AUTOSAR XML (schema 4-0-3)
package /ComponentTypes
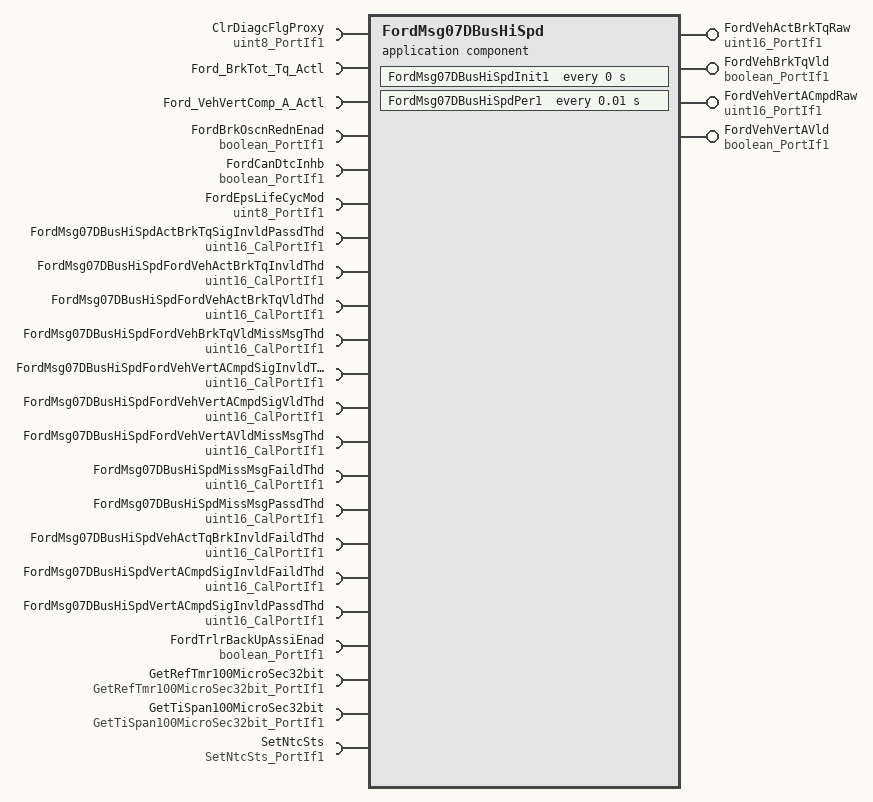
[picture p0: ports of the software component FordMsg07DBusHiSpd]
  application sw component type FordMsg07DBusHiSpd  # The purpose of the Ford Message 07D Bus High Speed function is to provide the Electric Power Steering system with signal values for the Brake Oscillation Reduction and Trailer Back Up Assist function from CAN. The Ford Message 07D function will perform the missing message diagnostic, signal invalid diagnostic, and provide a validity flag for the received message and signal values.']
    4 x provide port:
      FordVehActBrkTqRaw: nonqueued-sender-com-spec{data-element=Val, init-value=0}, provided-interface=uint16_PortIf1  # Processed value of Ford Vehicle Actual Brake Torque Raw to be used by EPS
      FordVehBrkTqVld: nonqueued-sender-com-spec{data-element=Logl, init-value=0}, provided-interface=boolean_PortIf1  # This signal Check the validity of Ford Vehicle Brake Torque
      FordVehVertACmpdRaw: nonqueued-sender-com-spec{data-element=Val, init-value=0}, provided-interface=uint16_PortIf1  # Processed value of Ford Vehicle Vertical Acceleration Compensated Raw to be used by EPS
      FordVehVertAVld: nonqueued-sender-com-spec{data-element=Logl, init-value=0}, provided-interface=boolean_PortIf1  # This signal Check the validity of Ford Vehicle Vertical Acceleration
    22 x require port:
      ClrDiagcFlgProxy: nonqueued-receiver-com-spec{data-element=Val, filter=data-filter-type=ALWAYS, init-value=0}, required-interface=uint8_PortIf1  # When ClrDiagcFlgProxy is True, Diagnostic test is performed
      Ford_BrkTot_Tq_Actl: nonqueued-receiver-com-spec{data-element=Ford_BrkTot_Tq_Actl, filter=data-filter-type=ALWAYS, init-value=0}, required-interface=Ford_BrkTot_Tq_Actl  # Ford Brake Total Torque Actual signal is a message signal which is received from CAN bus and which will be processed and used in EPS. Customer Data type : Ford_BrkTot_Tq_Actl,Source signal range: [0,8189], Cx1FFE_Unknown(8190) and Cx1FFF_Fault(8191)
      Ford_VehVertComp_A_Actl: nonqueued-receiver-com-spec{data-element=Ford_VehVertComp_A_Actl, filter=data-filter-type=ALWAYS, init-value=0}, required-interface=Ford_VehVertComp_A_Actl  # Ford Vehicle Vertical Compensated Acceleration Actual signal is a message signal which is received from CAN bus and which will be processed and used in EPS. Customer Data type : Ford_VehVertComp_A_Actl,Source signal range: [0,1021], Cx3FE_NoDataExists(1022) and Cx3FF_Fault(1023)
      FordBrkOscnRednEnad: nonqueued-receiver-com-spec{data-element=Logl, filter=data-filter-type=ALWAYS, init-value=0}, required-interface=boolean_PortIf1  # Ford Brake Oscillation Reduction Enabled signal is a message signal which is received from CAN bus and which will be used for Diagnostics of received message
      FordCanDtcInhb: nonqueued-receiver-com-spec{data-element=Logl, filter=data-filter-type=ALWAYS, init-value=1}, required-interface=boolean_PortIf1  # When CAN DTC Inhibit is FALSE, Diagnostic test is performed
      FordEpsLifeCycMod: nonqueued-receiver-com-spec{data-element=Val, filter=data-filter-type=ALWAYS, init-value=0}, required-interface=uint8_PortIf1  # This signal is used to decide calibration value to FAIL the NTC
      FordMsg07DBusHiSpdActBrkTqSigInvldPassdThd: parameter-require-com-spec{init-value=0, parameter=Val}, required-interface=uint16_CalPortIf1  # Threshold to update the Ford Vehicle Brake Torque Validity signal whenthe Ford Brake Total Torque Actual signal is invalid
      FordMsg07DBusHiSpdFordVehActBrkTqInvldThd: parameter-require-com-spec{init-value=0, parameter=Val}, required-interface=uint16_CalPortIf1  # Threshold to set Ford Vehicle Actual Brake Torque Invalid to False
      FordMsg07DBusHiSpdFordVehActBrkTqVldThd: parameter-require-com-spec{init-value=0, parameter=Val}, required-interface=uint16_CalPortIf1  # Threshold to set Ford Vehicle Actual Brake Torque Valid to True
      FordMsg07DBusHiSpdFordVehBrkTqVldMissMsgThd: parameter-require-com-spec{init-value=5000, parameter=Val}, required-interface=uint16_CalPortIf1  # Threshold to set Ford Vehicle Actual Brake Torque Valid to False
      FordMsg07DBusHiSpdFordVehVertACmpdSigInvldThd: parameter-require-com-spec{init-value=0, parameter=Val}, required-interface=uint16_CalPortIf1  # Threshold to set Ford Vehicle Vertical Acceleration Compensated Signal Invalid to False
      FordMsg07DBusHiSpdFordVehVertACmpdSigVldThd: parameter-require-com-spec{init-value=5000, parameter=Val}, required-interface=uint16_CalPortIf1  # Threshold to set Ford Vehicle Vertical Acceleration Compensated Signal Valid to True
      FordMsg07DBusHiSpdFordVehVertAVldMissMsgThd: parameter-require-com-spec{init-value=5000, parameter=Val}, required-interface=uint16_CalPortIf1  # Threshold to set Ford Vehicle Vertical Acceleration Compensated Signal Invalid to False
      FordMsg07DBusHiSpdMissMsgFaildThd: parameter-require-com-spec{init-value=5000, parameter=Val}, required-interface=uint16_CalPortIf1  # Threshold to set the Missing message NTC
      FordMsg07DBusHiSpdMissMsgPassdThd: parameter-require-com-spec{init-value=0, parameter=Val}, required-interface=uint16_CalPortIf1  # Threshold to reset the Missing message NTC
      FordMsg07DBusHiSpdVehActTqBrkInvldFaildThd: parameter-require-com-spec{init-value=0, parameter=Val}, required-interface=uint16_CalPortIf1  # Threshold to set the Ford Vehicle Actual Torque Brake Invalid NTC
      FordMsg07DBusHiSpdVertACmpdSigInvldFaildThd: parameter-require-com-spec{init-value=0, parameter=Val}, required-interface=uint16_CalPortIf1  # Threshold to set the Ford Vehicle Vertical Acceleration Compensated Signal Invalid NTC
      FordMsg07DBusHiSpdVertACmpdSigInvldPassdThd: parameter-require-com-spec{init-value=0, parameter=Val}, required-interface=uint16_CalPortIf1  # Threshold to reset the Ford Vehicle Vertical Acceleration Compensated Signal Invalid NTC
      FordTrlrBackUpAssiEnad: nonqueued-receiver-com-spec{data-element=Logl, filter=data-filter-type=ALWAYS, init-value=0}, required-interface=boolean_PortIf1  # Ford Trailer Back Up Assist Enabled signal is a message signal which is received from CAN bus and which will be used for Diagnostics of received message
      GetRefTmr100MicroSec32bit: client-com-spec=Oper, required-interface=GetRefTmr100MicroSec32bit_PortIf1  # It captures simulation time fromthe SimnTi value obtained at root layer of model and gives the RefTmr
      GetTiSpan100MicroSec32bit: client-com-spec=Oper, required-interface=GetTiSpan100MicroSec32bit_PortIf1  # It Captures simulation time fromSimnTi value, handles counter wrapping, and subtracts RefTmr,provides the TiSpan
      SetNtcSts: client-com-spec=Oper, required-interface=SetNtcSts_PortIf1  # Returns the NTC Qualifier status
    behavior FordMsg07DBusHiSpd_InternalBehavior
      ar-typed-per-instance-memorys:
        19 x data, all with sw-calibration-access=READ-ONLY:
          ClrDiagcFlgProxyPrev: type=uint8  # Clear Diagc Flag Proxy
          FirstTranVldFlg: type=boolean  # This flag is used to indicate the reception of first message
          FordVehActBrkTqRawPrev: type=uint16  # Holds previous value of FordVehActBrkTqRaw when FordMsg07D message is missing
          FordVehActBrkTqSigInvldFaildRefTi: type=uint32  # Timer for invalid message will increment or reset based on the conditions for NTC0x110
          FordVehActBrkTqSigInvldPassdRefTi: type=uint32  # Timer for invalid message will increment or reset based on the conditions for NTC0x110
          FordVehActBrkTqVldFaildRefTi: type=uint32  # Timer for Ford Vehicle Actual Brake Torque Valid Failed Reference Time will increment or reset based on the conditions
          FordVehActBrkTqVldPassdRefTi: type=uint32  # Timer for Ford Vehicle Actual Brake Torque Valid Passed Reference Time will increment or reset based on the conditions
          FordVehBrkTqVldMissMsgRefTi: type=uint32  # Timer to update Ford Vehicle Brake Torque Valid signal as true or false when FordMsg07D message is missing
          FordVehBrkTqVldPrev: type=boolean  # Holds previous value of FordVehBrkTqVld when FordMsg07D message is missing
          FordVehMsg07DMiss: type=boolean  # Flag for missing message diagnostics, it is true when message is missing
          FordVehVertACmpdRawPrev: type=uint16  # Holds previous value of FordVehVertACmpdRaw when FordMsg07D message is missing
          FordVehVertACmpdSigInvldFaildRefTi: type=uint32  # Timer for invalid message will increment or reset based on the conditions for NTC0x111
          FordVehVertACmpdSigInvldPassdRefTi: type=uint32  # Timer for invalid message will increment or reset based on the conditions for NTC0x111
          FordVehVertACmpdSigVldFaildRefTi: type=uint32  # Timer for Ford Vehicle Vertical Acceleration Compensated Signal Valid Failed Reference Time will increment or reset based on the conditions
          FordVehVertACmpdSigVldPassdRefTi: type=uint32  # Timer for Ford Vehicle Vertical Acceleration Compensated Signal Valid Passed Reference Time will increment or reset based on the conditions
          FordVehVertAVldMissMsgRefTi: type=uint32  # Timer for Ford Vehicle Vertical Acceleration Compensated Signal Valid Missing Reference Time will increment or reset based on the conditions
          FordVehVertAVldPrev: type=boolean  # Previous Value of Ford Vehicle Vertical Acceleration Valid
          MissMsgFaildRefTi: type=uint32  # Timer for missing message will increment or reset based on the conditions
          MissMsgPassdRefTi: type=uint32  # Timer for missing message will increment or reset based on the conditions
      timing event FordMsg07DBusHiSpd_InitEvent: start-on-event=FordMsg07DBusHiSpdInit1, period=0
      timing event TMT_FordMsg07DBusHiSpdPer1: start-on-event=FordMsg07DBusHiSpdPer1, period=0.01
      port-api-options:
        enable-take-address=false, indirect-api=false, port=ClrDiagcFlgProxy
        enable-take-address=false, indirect-api=false, port=Ford_BrkTot_Tq_Actl
        enable-take-address=false, indirect-api=false, port=Ford_VehVertComp_A_Actl
        enable-take-address=false, indirect-api=false, port=FordBrkOscnRednEnad
        enable-take-address=false, indirect-api=false, port=FordCanDtcInhb
        enable-take-address=false, indirect-api=false, port=FordEpsLifeCycMod
        enable-take-address=false, indirect-api=false, port=FordMsg07DBusHiSpdActBrkTqSigInvldPassdThd
        enable-take-address=false, indirect-api=false, port=FordMsg07DBusHiSpdFordVehActBrkTqInvldThd
        enable-take-address=false, indirect-api=false, port=FordMsg07DBusHiSpdFordVehBrkTqVldMissMsgThd
        enable-take-address=false, indirect-api=false, port=FordMsg07DBusHiSpdFordVehVertACmpdSigInvldThd
        enable-take-address=false, indirect-api=false, port=FordMsg07DBusHiSpdFordVehVertACmpdSigVldThd
        enable-take-address=false, indirect-api=false, port=FordMsg07DBusHiSpdFordVehVertAVldMissMsgThd
        enable-take-address=false, indirect-api=false, port=FordMsg07DBusHiSpdMissMsgFaildThd
        enable-take-address=false, indirect-api=false, port=FordMsg07DBusHiSpdMissMsgPassdThd
        enable-take-address=false, indirect-api=false, port=FordMsg07DBusHiSpdVehActTqBrkInvldFaildThd
        enable-take-address=false, indirect-api=false, port=FordMsg07DBusHiSpdVertACmpdSigInvldFaildThd
        enable-take-address=false, indirect-api=false, port=FordMsg07DBusHiSpdVertACmpdSigInvldPassdThd
        enable-take-address=false, indirect-api=false, port=FordTrlrBackUpAssiEnad
        enable-take-address=false, indirect-api=false, port=FordVehActBrkTqRaw
        enable-take-address=false, indirect-api=false, port=FordVehBrkTqVld
        enable-take-address=false, indirect-api=false, port=FordVehVertACmpdRaw
        enable-take-address=false, indirect-api=false, port=FordVehVertAVld
        enable-take-address=false, indirect-api=false, port=GetRefTmr100MicroSec32bit
        enable-take-address=false, indirect-api=false, port=GetTiSpan100MicroSec32bit
        enable-take-address=false, indirect-api=false, port=SetNtcSts
      runnable FordMsg07DBusHiSpdInit1  # Initialization Runnable
        sync call SC_GetRefTmr100MicroSec32bit_Oper: operation=GetRefTmr100MicroSec32bit.Oper, timeout=0
      runnable FordMsg07DBusHiSpdPer1: minimum-start-interval=0.01  # Periodic Runnable at 0.01sec
        data-receive-point-by-arguments:
          7 x access:
            REC_ClrDiagcFlgProxy_Val: accessed-variable=ClrDiagcFlgProxy.Val
            REC_Ford_BrkTot_Tq_Actl_Ford_BrkTot_Tq_Actl: accessed-variable=Ford_BrkTot_Tq_Actl.Ford_BrkTot_Tq_Actl
            REC_Ford_VehVertComp_A_Actl_Ford_VehVertComp_A_Actl: accessed-variable=Ford_VehVertComp_A_Actl.Ford_VehVertComp_A_Actl
            REC_FordBrkOscnRednEnad_Logl: accessed-variable=FordBrkOscnRednEnad.Logl
            REC_FordCanDtcInhb_Logl: accessed-variable=FordCanDtcInhb.Logl
            REC_FordEpsLifeCycMod_Val: accessed-variable=FordEpsLifeCycMod.Val
            REC_FordTrlrBackUpAssiEnad_Logl: accessed-variable=FordTrlrBackUpAssiEnad.Logl
        data-send-points:
          4 x access:
            SEND_FordVehActBrkTqRaw_Val: accessed-variable=FordVehActBrkTqRaw.Val
            SEND_FordVehBrkTqVld_Logl: accessed-variable=FordVehBrkTqVld.Logl
            SEND_FordVehVertACmpdRaw_Val: accessed-variable=FordVehVertACmpdRaw.Val
            SEND_FordVehVertAVld_Logl: accessed-variable=FordVehVertAVld.Logl
        sync call SC_GetRefTmr100MicroSec32bit_Oper: operation=GetRefTmr100MicroSec32bit.Oper, timeout=0
        sync call SC_GetTiSpan100MicroSec32bit_Oper: operation=GetTiSpan100MicroSec32bit.Oper, timeout=0
        sync call SC_SetNtcSts_Oper: operation=SetNtcSts.Oper, timeout=0
  swc implementation FordMsg07DBusHiSpd_Implementation: behavior=FordMsg07DBusHiSpd_InternalBehavior
    code-descriptors:
      code Default: artifact-descriptors=autosar-engineering-object={short-label=Default, category=SWSRC}
